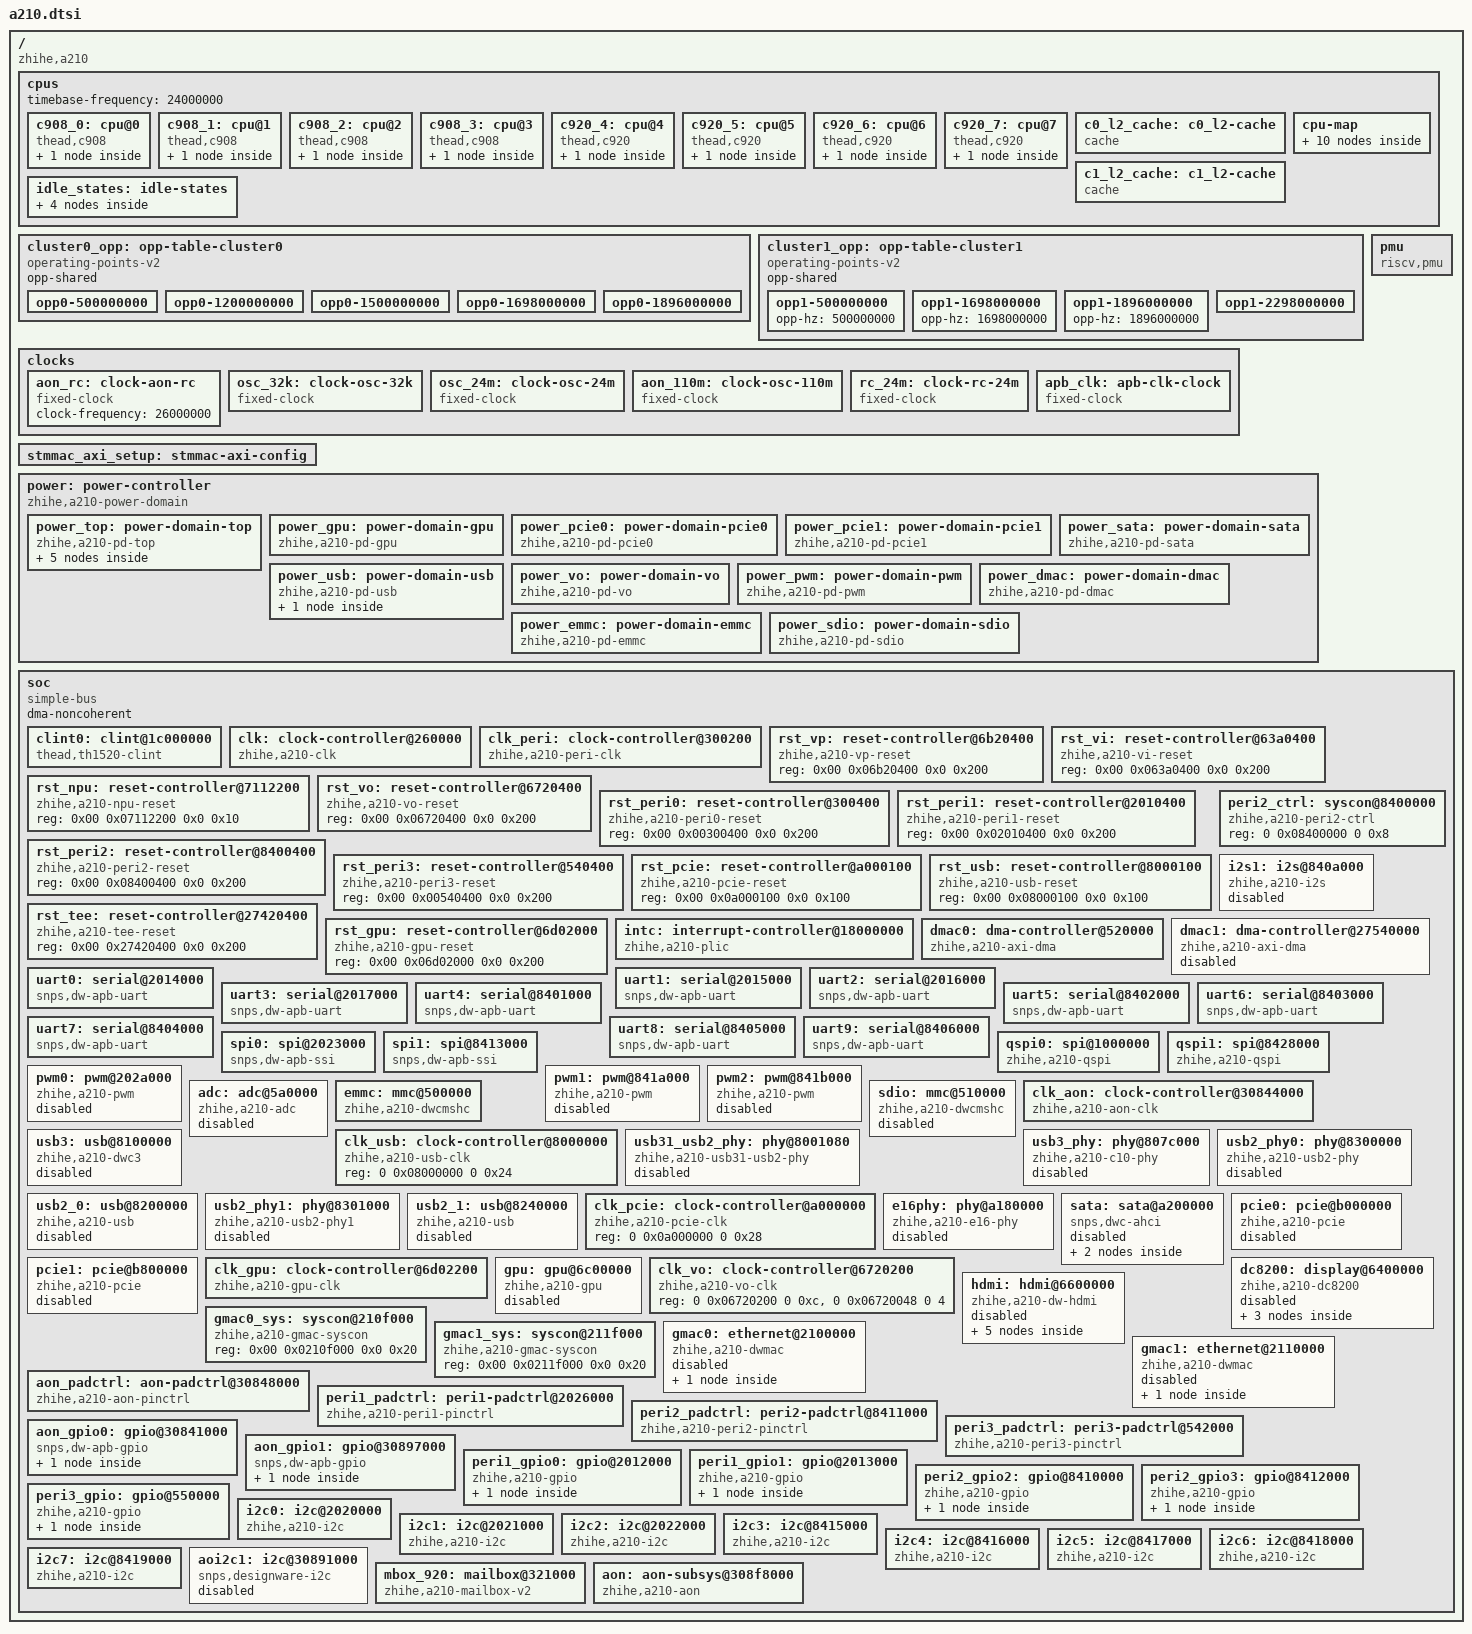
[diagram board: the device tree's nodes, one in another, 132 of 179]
// SPDX-License-Identifier: (GPL-2.0-only OR BSD-2-Clause)
/*
 * Copyright (C) 2021 Alibaba Group Holding Limited.
 */

#include <dt-bindings/ata/ahci.h>
#include <dt-bindings/clock/zhihe,a210-clk.h>
#include <dt-bindings/clock/zhihe,a210-aon-clk.h>
#include <dt-bindings/i2c/i2c.h>
#include <dt-bindings/interrupt-controller/irq.h>
#include <dt-bindings/reset/zhihe,a210-resets.h>

/ {
	compatible = "zhihe,a210";
	#address-cells = <2>;
	#size-cells = <2>;

	cpus: cpus {
		#address-cells = <1>;
		#size-cells = <0>;
		timebase-frequency = <24000000>; /*24M*/
		c908_0: cpu@0 {
			device_type = "cpu";
			reg = <0>;
			compatible = "thead,c908", "riscv";
			riscv,isa-base = "rv64i";
			riscv,isa-extensions = "i", "m", "a", "f", "d", "c", "b", "v",
					     "sscofpmf", "sstc", "svpbmt", "zba", "zbb",
					     "zbc", "zbs", "zicbom", "zicbop",
					     "zicboz", "zicntr", "zicsr",
					     "zifencei", "zihpm";
			riscv,cbom-block-size = <64>;
			riscv,cbop-block-size = <64>;
			riscv,cboz-block-size = <64>;
			mmu-type = "riscv,sv39";
			i-cache-block-size = <64>;
			i-cache-size = <32768>;
			i-cache-sets = <256>;
			d-cache-block-size = <64>;
			d-cache-size = <32768>;
			d-cache-sets = <256>;
			next-level-cache = <&c0_l2_cache>;
			capacity-dmips-mhz = <768>;
			clocks = <&clk C908_CPU_TO_CDE_CLK_MUX>;
			operating-points-v2 = <&cluster0_opp>;
			#cooling-cells = <2>;
			numa-node-id = <0>;
			status = "okay";
			cpu0_intc: interrupt-controller {
				#interrupt-cells = <1>;
				compatible = "riscv,cpu-intc";
				interrupt-controller;
			};
		};
		c908_1: cpu@1 {
			device_type = "cpu";
			reg = <1>;
			compatible = "thead,c908", "riscv";
			riscv,isa-base = "rv64i";
			riscv,isa-extensions = "i", "m", "a", "f", "d", "c", "b", "v",
					     "sscofpmf", "sstc", "svpbmt", "zba", "zbb",
					     "zbc", "zbs", "zicbom", "zicbop",
					     "zicboz", "zicntr", "zicsr",
					     "zifencei", "zihpm";
			riscv,cbom-block-size = <64>;
			riscv,cbop-block-size = <64>;
			riscv,cboz-block-size = <64>;
			mmu-type = "riscv,sv39";
			i-cache-block-size = <64>;
			i-cache-size = <32768>;
			i-cache-sets = <256>;
			d-cache-block-size = <64>;
			d-cache-size = <32768>;
			d-cache-sets = <256>;
			next-level-cache = <&c0_l2_cache>;
			capacity-dmips-mhz = <768>;
			operating-points-v2 = <&cluster0_opp>;
			#cooling-cells = <2>;
			numa-node-id = <0>;
			status = "okay";
			cpu1_intc: interrupt-controller {
				#interrupt-cells = <1>;
				compatible = "riscv,cpu-intc";
				interrupt-controller;
			};
		};
		c908_2: cpu@2 {
			device_type = "cpu";
			reg = <2>;
			compatible = "thead,c908", "riscv";
			riscv,isa-base = "rv64i";
			riscv,isa-extensions = "i", "m", "a", "f", "d", "c", "b", "v",
					     "sscofpmf", "sstc", "svpbmt", "zba", "zbb",
					     "zbc", "zbs", "zicbom", "zicbop",
					     "zicboz", "zicntr", "zicsr",
					     "zifencei", "zihpm";
			riscv,cbom-block-size = <64>;
			riscv,cbop-block-size = <64>;
			riscv,cboz-block-size = <64>;
			mmu-type = "riscv,sv39";
			i-cache-block-size = <64>;
			i-cache-size = <32768>;
			i-cache-sets = <256>;
			d-cache-block-size = <64>;
			d-cache-size = <32768>;
			d-cache-sets = <256>;
			next-level-cache = <&c0_l2_cache>;
			capacity-dmips-mhz = <768>;
			operating-points-v2 = <&cluster0_opp>;
			#cooling-cells = <2>;
			numa-node-id = <0>;
			status = "okay";
			cpu2_intc: interrupt-controller {
				#interrupt-cells = <1>;
				compatible = "riscv,cpu-intc";
				interrupt-controller;
			};
		};
		c908_3: cpu@3 {
			device_type = "cpu";
			reg = <3>;
			compatible = "thead,c908", "riscv";
			riscv,isa-base = "rv64i";
			riscv,isa-extensions = "i", "m", "a", "f", "d", "c", "b", "v",
					     "sscofpmf", "sstc", "svpbmt", "zba", "zbb",
					     "zbc", "zbs", "zicbom", "zicbop",
					     "zicboz", "zicntr", "zicsr",
					     "zifencei", "zihpm";
			riscv,cbom-block-size = <64>;
			riscv,cbop-block-size = <64>;
			riscv,cboz-block-size = <64>;
			mmu-type = "riscv,sv39";
			i-cache-block-size = <64>;
			i-cache-size = <32768>;
			i-cache-sets = <256>;
			d-cache-block-size = <64>;
			d-cache-size = <32768>;
			d-cache-sets = <256>;
			next-level-cache = <&c0_l2_cache>;
			capacity-dmips-mhz = <768>;
			operating-points-v2 = <&cluster0_opp>;
			#cooling-cells = <2>;
			numa-node-id = <0>;
			status = "okay";
			cpu3_intc: interrupt-controller {
				#interrupt-cells = <1>;
				compatible = "riscv,cpu-intc";
				interrupt-controller;
			};
		};

		c920_4: cpu@4 {
			device_type = "cpu";
			reg = <4>;
			compatible = "thead,c920", "riscv";
			riscv,isa-base = "rv64i";
			riscv,isa-extensions = "i", "m", "a", "f", "d", "c", "b", "v",
					     "sscofpmf", "sstc", "svpbmt", "zba", "zbb",
					     "zbc", "zbs", "zicbom", "zicbop",
					     "zicboz", "zicntr", "zicsr",
					     "zifencei", "zihpm";
			riscv,cbom-block-size = <64>;
			riscv,cbop-block-size = <64>;
			riscv,cboz-block-size = <64>;
			mmu-type = "riscv,sv39";
			i-cache-block-size = <64>;
			i-cache-size = <65536>;
			i-cache-sets = <512>;
			d-cache-block-size = <64>;
			d-cache-size = <65536>;
			d-cache-sets = <512>;
			next-level-cache = <&c1_l2_cache>;
			capacity-dmips-mhz = <1024>;
			clocks = <&clk C920_CPU_TO_CDE_CLK_MUX>;
			operating-points-v2 = <&cluster1_opp>;
			#cooling-cells = <2>;
			numa-node-id = <0>;
			status = "okay";
			cpu4_intc: interrupt-controller {
				#interrupt-cells = <1>;
				compatible = "riscv,cpu-intc";
				interrupt-controller;
			};
		};
		c920_5: cpu@5 {
			device_type = "cpu";
			reg = <5>;
			compatible = "thead,c920", "riscv";
			riscv,isa-base = "rv64i";
			riscv,isa-extensions = "i", "m", "a", "f", "d", "c", "b", "v",
					     "sscofpmf", "sstc", "svpbmt", "zba", "zbb",
					     "zbc", "zbs", "zicbom", "zicbop",
					     "zicboz", "zicntr", "zicsr",
					     "zifencei", "zihpm";
			riscv,cbom-block-size = <64>;
			riscv,cbop-block-size = <64>;
			riscv,cboz-block-size = <64>;
			mmu-type = "riscv,sv39";
			i-cache-block-size = <64>;
			i-cache-size = <65536>;
			i-cache-sets = <512>;
			d-cache-block-size = <64>;
			d-cache-size = <65536>;
			d-cache-sets = <512>;
			next-level-cache = <&c1_l2_cache>;
			capacity-dmips-mhz = <1024>;
			operating-points-v2 = <&cluster1_opp>;
			#cooling-cells = <2>;
			numa-node-id = <0>;
			status = "okay";
			cpu5_intc: interrupt-controller {
				#interrupt-cells = <1>;
				compatible = "riscv,cpu-intc";
				interrupt-controller;
			};
		};
		c920_6: cpu@6 {
			device_type = "cpu";
			reg = <6>;
			compatible = "thead,c920", "riscv";
			riscv,isa-base = "rv64i";
			riscv,isa-extensions = "i", "m", "a", "f", "d", "c", "b", "v",
					     "sscofpmf", "sstc", "svpbmt", "zba", "zbb",
					     "zbc", "zbs", "zicbom", "zicbop",
					     "zicboz", "zicntr", "zicsr",
					     "zifencei", "zihpm";
			riscv,cbom-block-size = <64>;
			riscv,cbop-block-size = <64>;
			riscv,cboz-block-size = <64>;
			mmu-type = "riscv,sv39";
			i-cache-block-size = <64>;
			i-cache-size = <65536>;
			i-cache-sets = <512>;
			d-cache-block-size = <64>;
			d-cache-size = <65536>;
			d-cache-sets = <512>;
			next-level-cache = <&c1_l2_cache>;
			capacity-dmips-mhz = <1024>;
			operating-points-v2 = <&cluster1_opp>;
			#cooling-cells = <2>;
			numa-node-id = <0>;
			status = "okay";
			cpu6_intc: interrupt-controller {
				#interrupt-cells = <1>;
				compatible = "riscv,cpu-intc";
				interrupt-controller;
			};
		};
		c920_7: cpu@7 {
			device_type = "cpu";
			reg = <7>;
			compatible = "thead,c920", "riscv";
			riscv,isa-base = "rv64i";
			riscv,isa-extensions = "i", "m", "a", "f", "d", "c", "b", "v",
					     "sscofpmf", "sstc", "svpbmt", "zba", "zbb",
					     "zbc", "zbs", "zicbom", "zicbop",
					     "zicboz", "zicntr", "zicsr",
					     "zifencei", "zihpm";
			riscv,cbom-block-size = <64>;
			riscv,cbop-block-size = <64>;
			riscv,cboz-block-size = <64>;
			mmu-type = "riscv,sv39";
			i-cache-block-size = <64>;
			i-cache-size = <65536>;
			i-cache-sets = <512>;
			d-cache-block-size = <64>;
			d-cache-size = <65536>;
			d-cache-sets = <512>;
			next-level-cache = <&c1_l2_cache>;
			capacity-dmips-mhz = <1024>;
			operating-points-v2 = <&cluster1_opp>;
			#cooling-cells = <2>;
			numa-node-id = <0>;
			status = "okay";
			cpu7_intc: interrupt-controller {
				#interrupt-cells = <1>;
				compatible = "riscv,cpu-intc";
				interrupt-controller;
			};
		};

		c0_l2_cache: c0_l2-cache {
			compatible = "cache";
			cache-block-size = <64>;
			cache-level = <2>;
			cache-size = <524288>;
			cache-sets = <512>;
			cache-unified;
		};
		c1_l2_cache: c1_l2-cache {
			compatible = "cache";
			cache-block-size = <64>;
			cache-level = <2>;
			cache-size = <1048576>;
			cache-sets = <1024>;
			cache-unified;
		};

		cpu-map {
			cluster0 {
				core0 {
					cpu = <&c908_0>;
				};

				core1 {
					cpu = <&c908_1>;
				};

				core2 {
					cpu = <&c908_2>;
				};

				core3 {
					cpu = <&c908_3>;
				};
			};
			cluster1 {
				core0 {
					cpu = <&c920_4>;
				};

				core1 {
					cpu = <&c920_5>;
				};

				core2 {
					cpu = <&c920_6>;
				};

				core3 {
					cpu = <&c920_7>;
				};
			};
		};

		idle_states: idle-states {
			CPU_RET_0_0: cpu-retentive-0-0 {
				compatible = "riscv,idle-state";
				riscv,sbi-suspend-param = <0x10000000>;
				entry-latency-us = <20>;
				exit-latency-us = <40>;
				min-residency-us = <80>;
			};

			CPU_NONRET_0_0: cpu-nonretentive-0-0 {
				compatible = "riscv,idle-state";
				riscv,sbi-suspend-param = <0x90000000>;
				entry-latency-us = <250>;
				exit-latency-us = <500>;
				min-residency-us = <950>;
			};

			CLUSTER_RET_0: cluster-retentive-0 {
				compatible = "riscv,idle-state";
				riscv,sbi-suspend-param = <0x11000000>;
				local-timer-stop;
				entry-latency-us = <50>;
				exit-latency-us = <100>;
				min-residency-us = <250>;
				wakeup-latency-us = <130>;
			};

			CLUSTER_NONRET_0: cluster-nonretentive-0 {
				compatible = "riscv,idle-state";
				riscv,sbi-suspend-param = <0x91000000>;
				local-timer-stop;
				entry-latency-us = <600>;
				exit-latency-us = <1100>;
				min-residency-us = <2700>;
				wakeup-latency-us = <1500>;
			};
		};
	};

	cluster0_opp: opp-table-cluster0 {
		compatible = "operating-points-v2";
		opp-shared;
		opp0-500000000 {
			opp-hz = /bits/ 64 <500000000>;
			bus-clk-hz = /bits/ 64 <196608000>;
			pic-clk-hz = /bits/ 64 <250000000>;
			cfg-clk-hz = /bits/ 64 <110000000>;
			com-clk-hz = /bits/ 64 <82500000>;
			apb-clk-hz = /bits/ 64 <82500000>;
		};
		opp0-1200000000 {
			opp-hz = /bits/ 64 <1200000000>;
			bus-clk-hz = /bits/ 64 <660000000>;
			pic-clk-hz = /bits/ 64 <500000000>;
			cfg-clk-hz = /bits/ 64 <220000000>;
			com-clk-hz = /bits/ 64 <165000000>;
			apb-clk-hz = /bits/ 64 <165000000>;
		};
		opp0-1500000000 {
			opp-hz = /bits/ 64 <1500000000>;
			bus-clk-hz = /bits/ 64 <1000000000>;
			pic-clk-hz = /bits/ 64 <1000000000>;
			cfg-clk-hz = /bits/ 64 <330000000>;
			com-clk-hz = /bits/ 64 <165000000>;
			apb-clk-hz = /bits/ 64 <165000000>;
		};
		opp0-1698000000 {
			opp-hz = /bits/ 64 <1698000000>;
			bus-clk-hz = /bits/ 64 <1100000000>;
			pic-clk-hz = /bits/ 64 <1000000000>;
			cfg-clk-hz = /bits/ 64 <330000000>;
			com-clk-hz = /bits/ 64 <165000000>;
			apb-clk-hz = /bits/ 64 <165000000>;
		};
		opp0-1896000000 {
			opp-hz = /bits/ 64 <1896000000>;
			bus-clk-hz = /bits/ 64 <1320000000>;
			pic-clk-hz = /bits/ 64 <1000000000>;
			cfg-clk-hz = /bits/ 64 <330000000>;
			com-clk-hz = /bits/ 64 <165000000>;
			apb-clk-hz = /bits/ 64 <165000000>;
		};
	};

	cluster1_opp: opp-table-cluster1 {
		compatible = "operating-points-v2";
		opp-shared;
		opp1-500000000 {
			opp-hz = /bits/ 64 <500000000>;
		};
		opp1-1698000000 {
			opp-hz = /bits/ 64 <1698000000>;
		};
		opp1-1896000000 {
			opp-hz = /bits/ 64 <1896000000>;
		};
		opp1-2298000000 {
			opp-hz = /bits/ 64 <2298000000>;
			turbo-mode;
		};
	};

	pmu {
		compatible = "riscv,pmu";
		riscv,event-to-mhpmevent =
			/* PMU_HW_CPU_CYCLES:1 */
			<0x00001 0x00000000 0x00000000>,
			/* PMU_HW_INSTRUCTIONS:2 */
			<0x00002 0x00000000 0x00000000>,
			/* PMU_HW_CACHE_REFERENCES:3 */
			/* PMU_HW_CACHE_MISSES:4 */
			/* PMU_HW_BRANCH_INSTRUCTIONS:5 */
			<0x00005 0x00000000 0x00000007>,
			/* PMU_HW_BRANCH_MISSES:6 */
			<0x00006 0x00000000 0x00000006>,
			/* PMU_HW_BUS_CYCLES:7 */
			/* PMU_HW_STALLED_CYCLES_FRONTEND:8 */
			<0x00008 0x00000000 0x00000027>,
			/* PMU_HW_STALLED_CYCLES_BACKEND:9 */
			<0x00009 0x00000000 0x00000028>,
			/* PMU_HW_REF_CPU_CYCLES:10 */
			/* L1D_READ_ACCESS:0x10000 */
			<0x10000 0x00000000 0x0000000c>,
			/* L1D_READ_MISS:0x10001 */
			<0x10001 0x00000000 0x0000000d>,
			/* L1D_WRITE_ACCESS:0x10002 */
			<0x10002 0x00000000 0x0000000e>,
			/* L1D_WRITE_MISS:0x10003 */
			<0x10003 0x00000000 0x0000000f>,
			/* L1I_READ_ACCESS:0x10008 */
			<0x10008 0x00000000 0x00000001>,
			/* L1I_READ_MISS:0x10009 */
			<0x10009 0x00000000 0x00000002>,
			/* dTLB read miss :0x10019 */
			<0x10019 0x00000000 0x00000004>,
			/* iTLB read miss :0x10021 */
			<0x10021 0x00000000 0x00000003>;
			/* LL_READ_ACCESS:0x10010 */
			/* LL_READ_MISS:0x10011 */
			/* LL_WRITE_ACCESS:0x10012 */
			/* LL_WRITE_MISS:0x10013 */
			/* BPU_READ_ACCESS:0x10028 */
			/* BPU_READ_MISS:0x10029 */
		riscv,event-to-mhpmcounters =
			/* 31 mhpmcounters, bitmap 0xfffffff8 */
			<0x00001 0x00001 0x00000001>,
			<0x00002 0x00002 0x00000004>,
			<0x00005 0x00005 0xfffffff8>,
			<0x00006 0x00006 0xfffffff8>,
			<0x00008 0x00008 0xfffffff8>,
			<0x00009 0x00009 0xfffffff8>,
			<0x10000 0x10000 0xfffffff8>,
			<0x10001 0x10001 0xfffffff8>,
			<0x10002 0x10002 0xfffffff8>,
			<0x10003 0x10003 0xfffffff8>,
			<0x10008 0x10008 0xfffffff8>,
			<0x10009 0x10009 0xfffffff8>,
			<0x10019 0x10019 0xfffffff8>,
			<0x10021 0x10021 0xfffffff8>;
		riscv,raw-event-to-mhpmcounters =
			/* For raw event ID 0x0 - 0xff */
			<0x0 0x0 0xffffffff 0xffffff00 0xfffffff8>;
	};

	clocks {


		aon_rc: clock-aon-rc {
			compatible = "fixed-clock";
			#clock-cells = <0>;
			clock-frequency = <26000000>;
		};

		osc_32k: clock-osc-32k {
			compatible = "fixed-clock";
			clock-frequency = <32768>;
			clock-output-names = "osc-32k";
			#clock-cells = <0>;
		};

		osc_24m: clock-osc-24m {
			compatible = "fixed-clock";
			clock-frequency = <24000000>;
			clock-output-names = "osc-24m";
			#clock-cells = <0>;
		};

		aon_110m: clock-osc-110m {
			compatible = "fixed-clock";
			clock-frequency = <110000000>;
			clock-output-names = "aon-110m";
			#clock-cells = <0>;
		};

		rc_24m: clock-rc-24m {
			compatible = "fixed-clock";
			clock-frequency = <24000000>;
			clock-output-names = "rc-24m";
			#clock-cells = <0>;
		};

		apb_clk: apb-clk-clock {
			compatible = "fixed-clock";
			clock-frequency = <62500000>;
			clock-output-names = "apb-clk";
			#clock-cells = <0>;
		};
	};

	stmmac_axi_setup: stmmac-axi-config {
		snps,wr_osr_lmt = <7>;
		snps,rd_osr_lmt = <7>;
		snps,blen = <16 8 4 0 0 0 0>;
	};

	power: power-controller {
		compatible = "zhihe,a210-power-domain";
		#power-domain-cells = <0>;
		#address-cells = <2>;
		#size-cells = <2>;
		ranges;

		power_top: power-domain-top {
			compatible = "zhihe,a210-pd-top";
			#power-domain-cells = <0>;
			#address-cells = <2>;
			#size-cells = <2>;
			ranges;
			ddr_ccu: clock-controller@5910000 {
				compatible = "zhihe,a210-ccu";
				reg = <0x00 0x05910000 0x0 0x2C>,
				      <0x00 0x05920000 0x0 0x2C>;
				zhihe,ccu-dly-time = <0x5E 0x5E>;
				zhihe,ccu-dly-time-step = <0x3 0x3>;
			};
			pcie_ccu: clock-controller@a007400 {
				compatible = "zhihe,a210-ccu";
				reg = <0x00 0x0A007400 0x0 0x2C>,
				      <0x00 0x0A008000 0x0 0x2C>,
				      <0x00 0x0A008400 0x0 0x2C>;
				zhihe,ccu-dly-time = <0x5E 0x5E 0x5E>;
				zhihe,ccu-dly-time-step = <0x3 0x3 0x3>;
			};
			tee_ccu: clock-controller@27430000 {
				compatible = "zhihe,a210-ccu";
				reg = <0x00 0x27430000 0x0 0x2C>;
				zhihe,ccu-dly-time = <0x5E>;
				zhihe,ccu-dly-time-step = <0x3>;
			};
			cpu_gating_ccu: clock-controller@10140000 {
				compatible = "zhihe,a210-ccu";
				reg = <0x00 0x10140000 0x0 0x2C>,
				      <0x00 0x10140200 0x0 0x2C>,
				      <0x00 0x10140400 0x0 0x2C>,
				      <0x00 0x10140600 0x0 0x2C>,
				      <0x00 0x10140A00 0x0 0x2C>,
				      <0x00 0x10140C00 0x0 0x2C>,
				      <0x00 0x10204000 0x0 0x2C>,
				      <0x00 0x10204200 0x0 0x2C>,
				      <0x00 0x10204400 0x0 0x2C>,
				      <0x00 0x10204600 0x0 0x2C>,
				      <0x00 0x10204800 0x0 0x2C>,
				      <0x00 0x10204A00 0x0 0x2C>,
				      <0x00 0x10205400 0x0 0x2C>;
				zhihe,ccu-dly-time = <0x34 0x34 0x34
						      0x34 0x34 0x34
						      0x34 0x34 0x34
						      0x34 0x34 0x34
						      0x34>;
				zhihe,ccu-dly-time-step = <0x2 0x2 0x2
							   0x2 0x2 0x2
							   0x2 0x2 0x2
							   0x2 0x2 0x2
							   0x2>;
			};
			cpu_scaling_ccu: clock-controller@10140800 {
				compatible = "zhihe,a210-ccu";
				reg = <0x00 0x10140800 0x0 0x2C>;
				zhihe,ccu-mode = <1>;
				zhihe,ccu-dly-time = <0x34>;
				zhihe,ccu-dly-time-step = <0x2>;
				zhihe,ccu-ratio = <63>;
			};
		};
		power_gpu: power-domain-gpu {
			compatible = "zhihe,a210-pd-gpu";
			reg = <0 0x06e00600 0 0x200>,
			      <0 0x06e00400 0 0x200>,
			      <0 0x06e00000 0 0x200>,
			      <0 0x26d12000 0 0x1000>;
			reg-names = "pca", "bpc", "pcu", "iopmp";
			power-domains = <&power_top>;
			clocks = <&clk TOP_GPU_CORE_CLK_DIV>;
			#power-domain-cells = <0>;
		};

		power_pcie0: power-domain-pcie0 {
			compatible = "zhihe,a210-pd-pcie0";
			reg = <0 0x0a006200 0 0x200>,
			      <0 0x0a006000 0 0x200>;
			reg-names = "bpc", "pcu";
			power-domains = <&power_top>;
			#power-domain-cells = <0>;
		};

		power_pcie1: power-domain-pcie1 {
			compatible = "zhihe,a210-pd-pcie1";
			reg = <0 0x0a006600 0 0x200>,
			      <0 0x0a006400 0 0x200>;
			reg-names = "bpc", "pcu";
			power-domains = <&power_top>;
			#power-domain-cells = <0>;
		};

		power_sata: power-domain-sata {
			compatible = "zhihe,a210-pd-sata";
			reg = <0 0x0a006a00 0 0x200>,
			      <0 0x0a006800 0 0x200>;
			reg-names = "bpc", "pcu";
			power-domains = <&power_top>;
			clocks = <&clk_pcie SATA_GEN3X2_ACLK_EN>,
				 <&clk_pcie SATA_PMALIVE_CLK_EN>,
				 <&clk_pcie SATA_MST_AFENCE_ACLK_EN>,
				 <&clk_pcie SATA_SLV_AFENCE_ACLK_EN>,
				 <&clk_pcie X2X_SATA_SLV_ACLK_EN>,
				 <&clk_pcie X2X_SATA_MST_ACLK_EN>,
				 <&clk_pcie SATA_RXOOB0_CLK_EN>,
				 <&clk_pcie SATA_RXOOB1_CLK_EN>;
			resets = <&rst_pcie PCIE_X2X_SATA_MST_ARST>,
				 <&rst_pcie PCIE_X2X_SATA_SLV_ARST>,
				 <&rst_pcie PCIE_SATA_SLV_AFENCE_ARST>,
				 <&rst_pcie PCIE_SATA_MST_AFENCE_ARST>,
				 <&rst_pcie PCIE_SATA_RST_ASIC0>,
				 <&rst_pcie PCIE_SATA_RST_ASIC1>,
				 <&rst_pcie PCIE_SATA_RST_RXOOB0>,
				 <&rst_pcie PCIE_SATA_RST_RXOOB1>;
			#power-domain-cells = <0>;
		};

		power_usb: power-domain-usb {
			compatible = "zhihe,a210-pd-usb";
			power-domains = <&power_top>;
			clocks = <&clk_usb USB_SS_AXI_MST_PCLK_EN>,
				 <&clk_usb USB_SS_AXI_MST_ACLK_EN>,
				 <&clk_usb USB_SS_DFMU_IOMMU_PTW_ACLK_EN>,
				 <&clk_usb USB_SS_DFMU_ACLK_EN>,
				 <&clk_usb USB_SS_DFMU_PCLK_EN>,
				 <&clk_usb USB31_SLV_AFENCE_ACLK_EN>,
				 <&clk_usb USB20_X2H_HCLK>,
				 <&clk_usb USB20_X2H_ACLK>,
				 <&clk_usb USB20_SLV_AFENCE_ACLK>,
				 <&clk_usb USB20_H2P_HCLK>,
				 <&clk_usb USB20_AHB_SLV_HCLK>,
				 <&clk_usb USB20_SYSREG_PCLK>,
				 <&clk_usb USB20_A2X0_HCLK>,
				 <&clk_usb USB20_A2X0_ACLK>,
				 <&clk_usb USB20_A2X1_HCLK>,
				 <&clk_usb USB20_A2X1_ACLK>,
				 <&clk_usb USB20_BUS_CLK>;
			resets = <&rst_usb USB_DFMU_PRST>,
				 <&rst_usb USB_DFMU_ARST>,
				 <&rst_usb USB_AXI4_MST_ARST>,
				 <&rst_usb USB_AXI4_MST_PRST>,
				 <&rst_usb USB_USB31_SLV_AFENCE_ARST>,
				 <&rst_usb USB_USB31_APBS_PRST>,
				 <&rst_usb USB_USB20_BLK_X2H_HRST>,
				 <&rst_usb USB_USB20_BLK_X2H_ARST>,
				 <&rst_usb USB_USB20_SLV_AFENCE_ARST>,
				 <&rst_usb USB_USB20_BLK_H2P_HRST>,
				 <&rst_usb USB_USB20_BLK_AHB_SLV_HRST>,
				 <&rst_usb USB_USB20_BLK_AXI_MST_ARST>,
				 <&rst_usb USB_USB20_BLK_USB2_SYSREG_PRST>,
				 <&rst_usb USB_USB20_BLK_USB2_WRAP0_PRST>,
				 <&rst_usb USB_USB20_BLK_USB2_WRAP1_PRST>,
				 <&rst_usb USB_USB20_BLK_A2X0_HRST>,
				 <&rst_usb USB_USB20_BLK_A2X0_ARST>,
				 <&rst_usb USB_USB20_BLK_A2X1_HRST>,
				 <&rst_usb USB_USB20_BLK_A2X1_ARST>;
			#power-domain-cells = <0>;
			#address-cells = <2>;
			#size-cells = <2>;
			ranges;

			usb_ccu: clock-controller@0 {
				compatible = "zhihe,a210-ccu";
				reg = <0x00 0x08004400 0x0 0x2C>,
				      <0x00 0x08006000 0x0 0x2C>,
				      <0x00 0x08006400 0x0 0x2C>;
				zhihe,ccu-dly-time = <0x5E 0x5E 0x5E>;
				zhihe,ccu-dly-time-step = <0x3 0x3 0x3>;
			};
		};

		power_vo: power-domain-vo {
			compatible = "zhihe,a210-pd-vo";
			reg = <0 0x067f1000 0 0x200>,
			      <0 0x067f0000 0 0x200>,
			      <0 0x06720000 0 0x1000>,
			      <0 0x26712000 0 0x1000>;
			reg-names = "bpc", "pcu", "syscon", "iopmp";
			power-domains = <&power_top>;
			clocks = <&clk_vo VO_X2H0_CLK_EN>,
				 <&clk_vo VO_X2H1_CLK_EN>,
				 <&clk_vo VO_ARB_PCLK_EN>,
				 <&clk_vo VO_ARB_ACLK_EN>,
				 <&clk_vo VO_DFMU_PCLK_EN>,
				 <&clk_vo VO_DFMU_ACLK_EN>,
				 <&clk_vo VO_PTW_ACLK_EN>;
			resets = <&rst_vo VO_X2H0_RST>, <&rst_vo VO_X2H1_RST>,
				 <&rst_vo VO_ARB_PRST>, <&rst_vo VO_ARB_ARST>,
				 <&rst_vo VO_DFMU_PRST>, <&rst_vo VO_DFMU_ARST>;
			#power-domain-cells = <0>;
		};

		power_pwm: power-domain-pwm {
			compatible = "zhihe,a210-pd-pwm";
			power-domains = <&power_top>;
			resets = <&rst_peri1 PERI1_PWM0_CRST>,
				 <&rst_peri1 PERI1_PWM0_PRST>,
				 <&rst_peri2 PERI2_PWM1_CRST>,
				 <&rst_peri2 PERI2_PWM1_PRST>,
				 <&rst_peri2 PERI2_PWM2_CRST>,
				 <&rst_peri2 PERI2_PWM2_PRST>;
			#power-domain-cells = <0>;
		};

		power_dmac: power-domain-dmac {
			compatible = "zhihe,a210-pd-dmac";
			power-domains = <&power_top>;
			clocks = <&clk_peri AXI_PERI3_MST_ACLK_EN>,
				 <&clk_peri AXI_PERI3_MST_PCLK_EN>;
			#power-domain-cells = <0>;
		};

		power_emmc: power-domain-emmc {
			compatible = "zhihe,a210-pd-emmc";
			power-domains = <&power_top>;
			#power-domain-cells = <0>;
			clocks = <&clk_peri AXI_PERI3_MST_ACLK_EN>,
				 <&clk_peri AXI_PERI3_MST_PCLK_EN>,
				 <&clk_peri PERI3_EMMC_ACLK_EN>,
				<&clk_peri PERI3_EMMC_X2X_ACLK_S_EN>,
				<&clk_peri PERI3_EMMC_X2X_ACLK_M_EN>,
				<&clk_peri PERI3_EMMC_OSC_CLK_EN>;
		};
		power_sdio: power-domain-sdio {
			compatible = "zhihe,a210-pd-sdio";
			power-domains = <&power_top>;
			#power-domain-cells = <0>;
			clocks = <&clk_peri AXI_PERI3_MST_ACLK_EN>,
				 <&clk_peri AXI_PERI3_MST_PCLK_EN>,
				 <&clk_peri PERI3_SDIO_ACLK_EN>,
				<&clk_peri PERI3_SDIO_X2X_ACLK_S_EN>,
				<&clk_peri PERI3_SDIO_X2X_ACLK_M_EN>,
				<&clk_peri PERI3_SDIO_OSC_CLK_EN>;
		};
	};

	soc {
		compatible = "simple-bus";
		#address-cells = <2>;
		#size-cells = <2>;
		ranges;
		dma-noncoherent;

		clint0: clint@1c000000 {
			compatible = "thead,th1520-clint", "thead,c900-clint";
			interrupts-extended = <
				&cpu0_intc  3 &cpu0_intc  7
				&cpu1_intc  3 &cpu1_intc  7
				&cpu2_intc  3 &cpu2_intc  7
				&cpu3_intc  3 &cpu3_intc  7
				&cpu4_intc  3 &cpu4_intc  7
				&cpu5_intc  3 &cpu5_intc  7
				&cpu6_intc  3 &cpu6_intc  7
				&cpu7_intc  3 &cpu7_intc  7
			>;
			reg = <0x00 0x1c000000 0x0 0x0000d800>;
		};

		clk: clock-controller@260000 {
			compatible = "zhihe,a210-clk";
			reg = <0x00 0x00260000 0x0 0x1000>,<0x00 0x00250000 0x0 0x1000>,
			      <0x00 0x10141600 0x0 0x100>,<0x00 0x10141400 0x0 0x100>,
			      <0x00 0x04810000 0x0 0x1000>,<0x00 0x05810000 0x0 0x1000>,
			      <0x00 0x04900000 0x0 0x1000>,<0x00 0x20250000 0x0 0x1000>,
			      <0x00 0x10140000 0x0 0xE00>;
			reg-names = "pll-wrap","top-crg","cpu-ss-clk-sysreg","cpu-ss-cpu-pll",
			"ddr0-sysreg","ddr1-sysreg","slc-dual-sysreg","top-crg-t","cpu-ss-ccu";
			#clock-cells = <1>;
			clocks = <&osc_32k>, <&osc_24m>, <&rc_24m>;
			clock-names = "osc-32k", "osc-24m", "rc-24m";
			status = "okay";
		};

		clk_peri: clock-controller@300200 {
			compatible = "zhihe,a210-peri-clk";
			reg = <0x00 0x00300200 0x0 0x4>,
			      <0x00 0x02010200 0x0 0x8>,<0x00 0x08400200 0x0 0x8>,
			      <0x00 0x00540200 0x0 0x4>,<0x00 0x27420200 0x0 0x200>;
			reg-names = "peri0-sysreg","peri1-sysreg","peri2-sysreg",
			"peri3-sysreg","tee-crg";
			#clock-cells = <1>;
			status = "okay";
		};

		rst_vp: reset-controller@6b20400 {
			compatible = "zhihe,a210-vp-reset";
			reg = <0x00 0x06b20400 0x0 0x200>;
			#reset-cells = <1>;
		};

		rst_vi: reset-controller@63a0400 {
			compatible = "zhihe,a210-vi-reset";
			reg = <0x00 0x063a0400 0x0 0x200>;
			#reset-cells = <1>;
		};

		rst_npu: reset-controller@7112200 {
			compatible = "zhihe,a210-npu-reset";
			reg = <0x00 0x07112200 0x0 0x10>;
			#reset-cells = <1>;
		};

		rst_vo: reset-controller@6720400 {
			compatible = "zhihe,a210-vo-reset";
			reg = <0x00 0x06720400 0x0 0x200>;
			#reset-cells = <1>;
		};

		rst_peri0: reset-controller@300400 {
			compatible = "zhihe,a210-peri0-reset";
			reg = <0x00 0x00300400 0x0 0x200>;
			#reset-cells = <1>;
		};

		rst_peri1: reset-controller@2010400 {
			compatible = "zhihe,a210-peri1-reset";
			reg = <0x00 0x02010400 0x0 0x200>;
			#reset-cells = <1>;
		};

		rst_peri2: reset-controller@8400400 {
			compatible = "zhihe,a210-peri2-reset";
			reg = <0x00 0x08400400 0x0 0x200>;
			#reset-cells = <1>;
		};

		rst_peri3: reset-controller@540400 {
			compatible = "zhihe,a210-peri3-reset";
			reg = <0x00 0x00540400 0x0 0x200>;
			#reset-cells = <1>;
		};

		rst_pcie: reset-controller@a000100 {
			compatible = "zhihe,a210-pcie-reset";
			reg = <0x00 0x0a000100 0x0 0x100>;
			#reset-cells = <1>;
		};

		rst_usb: reset-controller@8000100 {
			compatible = "zhihe,a210-usb-reset";
			reg = <0x00 0x08000100 0x0 0x100>;
			#reset-cells = <1>;
		};

		rst_tee: reset-controller@27420400 {
			compatible = "zhihe,a210-tee-reset";
			reg = <0x00 0x27420400 0x0 0x200>;
			#reset-cells = <1>;
		};

		rst_gpu: reset-controller@6d02000 {
			compatible = "zhihe,a210-gpu-reset";
			reg = <0x00 0x06d02000 0x0 0x200>;
			#reset-cells = <1>;
		};

		intc: interrupt-controller@18000000 {
			compatible = "zhihe,a210-plic", "thead,c900-plic";
			#address-cells = <0>;
			#interrupt-cells = <2>;
			interrupt-controller;
			interrupts-extended = <
				&cpu0_intc 0xffffffff &cpu0_intc 9
				&cpu1_intc 0xffffffff &cpu1_intc 9
				&cpu2_intc 0xffffffff &cpu2_intc 9
				&cpu3_intc 0xffffffff &cpu3_intc 9
				&cpu4_intc 0xffffffff &cpu4_intc 9
				&cpu5_intc 0xffffffff &cpu5_intc 9
				&cpu6_intc 0xffffffff &cpu6_intc 9
				&cpu7_intc 0xffffffff &cpu7_intc 9
			>;
			reg = <0x00 0x18000000 0x0 0x04000000>;
			riscv,ndev = <351>;
		};

		peri2_ctrl: syscon@8400000 {
			compatible = "zhihe,a210-peri2-ctrl", "syscon";
			reg = <0 0x08400000 0 0x8>;
		};

		i2s1: i2s@840a000 {
			compatible = "zhihe,a210-i2s";
			zhihe,syscon = <&peri2_ctrl 0 0x1>;
			reg = <0 0x0840a000 0 0x1000>;
			interrupt-parent = <&intc>;
			interrupts = <302 IRQ_TYPE_LEVEL_HIGH>;
			clocks = <&clk_peri PERI2_I2S1_PCLK_EN>,
				 <&clk_peri PERI2_I2S1_SRC_CLK_EN>;
			clock-names = "pclk", "mclk";
			resets = <&rst_peri2 PERI2_I2S1_PRST>;
			power-domains = <&power_top>;
			dmas = <&dmac0 38>, <&dmac0 37>;
			dma-names = "tx", "rx";
			#sound-dai-cells = <0>;
			status = "disabled";
		};

		dmac0: dma-controller@520000 {
			compatible = "zhihe,a210-axi-dma", "snps,axi-dma-1.01a";
			reg = <0x00 0x00520000 0x0 0x4000>;
			interrupt-parent = <&intc>;
			interrupts = <264 IRQ_TYPE_LEVEL_HIGH>;
			clocks = <&clk_peri PERI3_DMAC_ACLK_EN>, <&clk_peri PERI3_DMAC_HCLK_EN>;
			clock-names = "core-clk", "cfgr-clk";
			resets = <&rst_peri3 PERI3_DMAC_ARST>, <&rst_peri3 PERI3_DMAC_HRST>;
			power-domains = <&power_dmac>;
			#dma-cells = <1>;
			dma-channels = <16>;
			snps,block-size = <65536 65536 65536 65536
					    65536 65536 65536 65536
					    65536 65536 65536 65536
					    65536 65536 65536 65536>;
			snps,priority = <0 0 0 0 0 0 0 0 0 0 0 0 0 0 0 0>;
			snps,dma-masters = <1>;
			snps,data-width = <4>;
			snps,axi-max-burst-len = <4>;
		};

		dmac1: dma-controller@27540000 {
			compatible = "zhihe,a210-axi-dma", "snps,axi-dma-1.01a";
			reg = <0x00 0x27540000 0x0 0x4000>;
			interrupt-parent = <&intc>;
			interrupts = <259 IRQ_TYPE_LEVEL_HIGH>;
			clocks = <&clk_peri TEE_DMAC_CLKEN>, <&clk_peri TEE_DMAC_CLKEN>;
			clock-names = "core-clk", "cfgr-clk";
			resets = <&rst_tee TEE_DMAC_ARST>, <&rst_tee TEE_DMAC_HRST>;
			#dma-cells = <1>;
			dma-channels = <4>;
			snps,block-size = <65536 65536 65536 65536>;
			snps,priority = <0 0 0 0>;
			snps,dma-masters = <1>;
			snps,data-width = <4>;
			snps,axi-max-burst-len = <16>;
			status = "disabled";
		};

		uart0: serial@2014000 {
			compatible = "snps,dw-apb-uart";
			reg = <0x00 0x02014000 0x0 0x400>;
			interrupt-parent = <&intc>;
			interrupts = <321 IRQ_TYPE_LEVEL_HIGH>;
			clocks = <&clk_peri PERI1_UART0_SCLK_EN>, <&clk_peri PERI1_UART0_PCLK_EN>;
			clock-names = "baudclk", "apb_pclk";
			resets = <&rst_peri1 PERI1_UART0_PRST>;
			reg-shift = <2>;
			reg-io-width = <4>;
		};

		uart1: serial@2015000 {
			compatible = "snps,dw-apb-uart";
			reg = <0x00 0x02015000 0x0 0x1000>;
			interrupt-parent = <&intc>;
			interrupts = <322 IRQ_TYPE_LEVEL_HIGH>;
			clocks = <&clk_peri PERI1_UART1_SCLK_EN>, <&clk_peri PERI1_UART1_PCLK_EN>;
			clock-names = "baudclk", "apb_pclk";
			resets = <&rst_peri1 PERI1_UART1_PRST>;
			reg-shift = <2>;
			reg-io-width = <4>;
		};

		uart2: serial@2016000 {
			compatible = "snps,dw-apb-uart";
			reg = <0x00 0x02016000 0x0 0x1000>;
			interrupt-parent = <&intc>;
			interrupts = <323 IRQ_TYPE_LEVEL_HIGH>;
			clocks = <&clk_peri PERI1_UART2_SCLK_EN>, <&clk_peri PERI1_UART2_PCLK_EN>;
			clock-names = "baudclk", "apb_pclk";
			resets = <&rst_peri1 PERI1_UART2_PRST>;
			reg-shift = <2>;
			reg-io-width = <4>;
		};

		uart3: serial@2017000 {
			compatible = "snps,dw-apb-uart";
			reg = <0x00 0x02017000 0x0 0x1000>;
			interrupt-parent = <&intc>;
			interrupts = <324 IRQ_TYPE_LEVEL_HIGH>;
			clocks = <&clk_peri PERI1_UART3_SCLK_EN>, <&clk_peri PERI1_UART3_PCLK_EN>;
			clock-names = "baudclk", "apb_pclk";
			resets = <&rst_peri1 PERI1_UART3_PRST>;
			reg-shift = <2>;
			reg-io-width = <4>;
		};

		uart4: serial@8401000 {
			compatible = "snps,dw-apb-uart";
			reg = <0x00 0x08401000 0x0 0x400>;
			interrupt-parent = <&intc>;
			interrupts = <325 IRQ_TYPE_LEVEL_HIGH>;
			clocks = <&clk_peri PERI2_UART4_SCLK_EN>, <&clk_peri PERI2_UART4_PCLK_EN>;
			clock-names = "baudclk", "apb_pclk";
			/* Firmware has already configured the boot console UART. */
			reg-shift = <2>;
			reg-io-width = <4>;
		};

		uart5: serial@8402000 {
			compatible = "snps,dw-apb-uart";
			reg = <0x00 0x08402000 0x0 0x1000>;
			interrupt-parent = <&intc>;
			interrupts = <326 IRQ_TYPE_LEVEL_HIGH>;
			clocks = <&clk_peri PERI2_UART5_SCLK_EN>, <&clk_peri PERI2_UART5_PCLK_EN>;
			clock-names = "baudclk", "apb_pclk";
			resets = <&rst_peri2 PERI2_UART5_PRST>;
			reg-shift = <2>;
			reg-io-width = <4>;
		};

		uart6: serial@8403000 {
			compatible = "snps,dw-apb-uart";
			reg = <0x00 0x08403000 0x0 0x1000>;
			interrupt-parent = <&intc>;
			interrupts = <327 IRQ_TYPE_LEVEL_HIGH>;
			clocks = <&clk_peri PERI2_UART6_SCLK_EN>, <&clk_peri PERI2_UART6_PCLK_EN>;
			clock-names = "baudclk", "apb_pclk";
			resets = <&rst_peri2 PERI2_UART6_PRST>;
			reg-shift = <2>;
			reg-io-width = <4>;
		};

		uart7: serial@8404000 {
			compatible = "snps,dw-apb-uart";
			reg = <0x00 0x08404000 0x0 0x1000>;
			interrupt-parent = <&intc>;
			interrupts = <328 IRQ_TYPE_LEVEL_HIGH>;
			clocks = <&clk_peri PERI2_UART7_SCLK_EN>, <&clk_peri PERI2_UART7_PCLK_EN>;
			clock-names = "baudclk", "apb_pclk";
			resets = <&rst_peri2 PERI2_UART7_PRST>;
			reg-shift = <2>;
			reg-io-width = <4>;
		};

		uart8: serial@8405000 {
			compatible = "snps,dw-apb-uart";
			reg = <0x00 0x08405000 0x0 0x1000>;
			interrupt-parent = <&intc>;
			interrupts = <329 IRQ_TYPE_LEVEL_HIGH>;
			clocks = <&clk_peri PERI2_UART8_SCLK_EN>, <&clk_peri PERI2_UART8_PCLK_EN>;
			clock-names = "baudclk", "apb_pclk";
			resets = <&rst_peri2 PERI2_UART8_PRST>;
			reg-shift = <2>;
			reg-io-width = <4>;
		};

		uart9: serial@8406000 {
			compatible = "snps,dw-apb-uart";
			reg = <0x00 0x08406000 0x0 0x1000>;
			interrupt-parent = <&intc>;
			interrupts = <330 IRQ_TYPE_LEVEL_HIGH>;
			clocks = <&clk_peri PERI2_UART9_SCLK_EN>, <&clk_peri PERI2_UART9_PCLK_EN>;
			clock-names = "baudclk", "apb_pclk";
			resets = <&rst_peri2 PERI2_UART9_PRST>;
			reg-shift = <2>;
			reg-io-width = <4>;
		};

		spi0: spi@2023000 {
			compatible = "snps,dw-apb-ssi";
			reg = <0x00 0x02023000 0x0 0x1000>;
			interrupt-parent = <&intc>;
			interrupts = <310 IRQ_TYPE_LEVEL_HIGH>;
			clocks = <&clk_peri PERI1_SPI0_SSI_CLK_EN>,
				 <&clk_peri PERI1_SPI0_PCLK_EN>;
			clock-names = "ssi_clk", "pclk";
			resets = <&rst_peri1 PERI1_SPI0_RST>;
			reset-names = "spi";
			power-domains = <&power_top>;
			dmas = <&dmac0 9>, <&dmac0 8>;
			dma-names = "tx", "rx";
			num-cs = <2>;
			#address-cells = <1>;
			#size-cells = <0>;
		};

		spi1: spi@8413000 {
			compatible = "snps,dw-apb-ssi";
			reg = <0x00 0x08413000 0x0 0x1000>;
			interrupt-parent = <&intc>;
			interrupts = <311 IRQ_TYPE_LEVEL_HIGH>;
			clocks = <&clk_peri PERI2_SPI1_SSI_CLK_EN>,
				 <&clk_peri PERI2_SPI1_PCLK_EN>;
			clock-names = "ssi_clk", "pclk";
			resets = <&rst_peri2 PERI2_SPI1_RST>;
			reset-names = "spi";
			power-domains = <&power_top>;
			dmas = <&dmac0 62>, <&dmac0 61>;
			dma-names = "tx", "rx";
			num-cs = <2>;
			#address-cells = <1>;
			#size-cells = <0>;
		};

		qspi0: spi@1000000 {
			compatible = "zhihe,a210-qspi", "snps,dwc-ssi-1.01a";
			reg = <0x00 0x01000000 0x0 0x4000>;
			interrupt-parent = <&intc>;
			interrupts = <308 IRQ_TYPE_LEVEL_HIGH>;
			clocks = <&clk_peri PERI1_QSPI0_SSI_CLK_EN>,
				 <&clk_peri PERI1_QSPI0_PCLK_EN>;
			clock-names = "ssi_clk", "pclk";
			resets = <&rst_peri1 PERI1_QSPI0_SSI_RST>,
				 <&rst_peri1 PERI1_QSPI0_PRST>;
			power-domains = <&power_top>;
			num-cs = <2>;
			#address-cells = <1>;
			#size-cells = <0>;
		};

		qspi1: spi@8428000 {
			compatible = "zhihe,a210-qspi", "snps,dwc-ssi-1.01a";
			reg = <0x00 0x08428000 0x0 0x4000>;
			interrupt-parent = <&intc>;
			interrupts = <309 IRQ_TYPE_LEVEL_HIGH>;
			clocks = <&clk_peri PERI2_QSPI1_SSI_CLK_EN>,
				 <&clk_peri PERI2_QSPI1_PCLK_EN>;
			clock-names = "ssi_clk", "pclk";
			resets = <&rst_peri2 PERI2_QSPI1_SSI_RST>,
				 <&rst_peri2 PERI2_QSPI1_PRST>;
			power-domains = <&power_top>;
			num-cs = <2>;
			#address-cells = <1>;
			#size-cells = <0>;
		};

		pwm0: pwm@202a000 {
			compatible = "zhihe,a210-pwm", "thead,th1520-pwm";
			reg = <0 0x0202a000 0 0x1000>;
			clocks = <&clk_peri PERI1_PWM0_CCLK_EN>;
			power-domains = <&power_pwm>;
			#pwm-cells = <3>;
			status = "disabled";
		};

		pwm1: pwm@841a000 {
			compatible = "zhihe,a210-pwm", "thead,th1520-pwm";
			reg = <0 0x0841a000 0 0x1000>;
			clocks = <&clk_peri PERI2_PWM1_CCLK_EN>;
			power-domains = <&power_pwm>;
			#pwm-cells = <3>;
			status = "disabled";
		};

		pwm2: pwm@841b000 {
			compatible = "zhihe,a210-pwm", "thead,th1520-pwm";
			reg = <0 0x0841b000 0 0x1000>;
			clocks = <&clk_peri PERI2_PWM2_CCLK_EN>;
			power-domains = <&power_pwm>;
			#pwm-cells = <3>;
			status = "disabled";
		};

		adc: adc@5a0000 {
			compatible = "zhihe,a210-adc";
			reg = <0 0x005a0000 0 0x1000>;
			clocks = <&clk_peri PERI3_ADC_PCLK_EN>;
			resets = <&rst_peri3 PERI3_ADC_PRST>;
			interrupt-parent = <&intc>;
			interrupts = <260 IRQ_TYPE_LEVEL_HIGH>;
			power-domains = <&power_top>;
			#io-channel-cells = <1>;
			status = "disabled";
		};

		emmc: mmc@500000 {
			compatible = "zhihe,a210-dwcmshc";
			reg = <0x0 0x00500000 0x0 0x10000>;
			interrupt-parent = <&intc>;
			interrupts = <265 IRQ_TYPE_LEVEL_HIGH>;
			clocks = <&clk_peri PERI3_EMMC_SDIO_REF_CLK_CG_EN>,
					 <&clk_peri PERI3_EMMC_HCLK_EN>;
			clock-names = "core", "bus";
			power-domains = <&power_emmc>;
		};

		sdio: mmc@510000 {
			compatible = "zhihe,a210-dwcmshc";
			reg = <0 0x00510000 0 0x10000>;
			interrupt-parent = <&intc>;
			interrupts = <337 IRQ_TYPE_LEVEL_HIGH>;
			clocks = <&clk_peri PERI3_EMMC_SDIO_REF_CLK_CG_EN>,
				 <&clk_peri PERI3_SDIO_HCLK_EN>;
			clock-names = "core", "bus";
			power-domains = <&power_sdio>;
			status = "disabled";
		};

		clk_aon: clock-controller@30844000 {
			compatible = "zhihe,a210-aon-clk";
			reg = <0 0x30844000 0 0x1c>;
			clocks = <&aon_110m>, <&osc_24m>, <&aon_rc>, <&osc_32k>;
			clock-names = "high", "osc", "rc", "rtc";
			#clock-cells = <1>;
		};


		clk_usb: clock-controller@8000000 {
			compatible = "zhihe,a210-usb-clk";
			reg = <0 0x08000000 0 0x24>;
			reg-names = "usb-clk-en";
			#clock-cells = <1>;
		};

		usb31_usb2_phy: phy@8001080 {
			compatible = "zhihe,a210-usb31-usb2-phy";
			reg = <0 0x08001080 0 0x28>;
			clocks = <&clk_usb USB31_PCLK_EN>;
			clock-names = "apb";
			resets = <&rst_usb USB_USB31_PHY_RST>;
			reset-names = "phy";
			power-domains = <&power_usb>;
			#phy-cells = <0>;
			status = "disabled";
		};

		usb3_phy: phy@807c000 {
			compatible = "zhihe,a210-c10-phy";
			reg = <0 0x0807c000 0 0x100>;
			clocks = <&clk_usb C10PHY_PCLK_EN>,
				 <&clk_usb USB31_REF_CLK_EN>,
				 <&clk_usb C10PHY_SUSPEND_CLK_EN>;
			clock-names = "apb", "ref", "suspend";
			resets = <&rst_usb USB_C10PHY_APBS_PRST>,
				 <&rst_usb USB_C10PHY_PHY_RST>;
			reset-names = "apb", "phy";
			power-domains = <&power_usb>;
			#phy-cells = <0>;
			status = "disabled";
		};

		usb3: usb@8100000 {
			compatible = "zhihe,a210-dwc3", "snps,dwc3";
			reg = <0 0x08100000 0 0x100000>;
			interrupt-parent = <&intc>;
			interrupts = <183 IRQ_TYPE_LEVEL_HIGH>;
			clocks = <&clk_usb USB31_BUS_CLK_EN>,
				 <&clk_usb USB31_REF_CLK_EN>,
				 <&clk_usb USB31_SUSPEND_CLK_EN>;
			clock-names = "bus_early", "ref", "suspend";
			resets = <&rst_usb USB_USB31_VCC_RST>;
			phys = <&usb31_usb2_phy>, <&usb3_phy>;
			phy-names = "usb2-phy", "usb3-phy";
			power-domains = <&power_usb>;
			status = "disabled";
		};

		usb2_phy0: phy@8300000 {
			compatible = "zhihe,a210-usb2-phy";
			reg = <0 0x08300000 0 0x20>;
			clocks = <&clk_usb USB20_SYSREG_PCLK>;
			clock-names = "apb";
			resets = <&rst_usb USB_USB20_BLK_USB0_PHY_PON_RESET>;
			reset-names = "phy";
			power-domains = <&power_usb>;
			#phy-cells = <0>;
			status = "disabled";
		};

		usb2_0: usb@8200000 {
			compatible = "zhihe,a210-usb", "snps,dwc2";
			reg = <0 0x08200000 0 0x40000>;
			interrupt-parent = <&intc>;
			interrupts = <181 IRQ_TYPE_LEVEL_HIGH>;
			clocks = <&clk_usb USB20_WRAP0_HCLK>;
			clock-names = "otg";
			resets = <&rst_usb USB_USB20_BLK_USB2_WRAP0_HRST>;
			reset-names = "dwc2";
			phys = <&usb2_phy0>;
			phy-names = "usb2-phy";
			power-domains = <&power_usb>;
			maximum-speed = "high-speed";
			g-rx-fifo-size = <275>;
			g-np-tx-fifo-size = <16>;
			g-tx-fifo-size = <256 128 128 64 64 32>;
			status = "disabled";
		};

		usb2_phy1: phy@8301000 {
			compatible = "zhihe,a210-usb2-phy1";
			reg = <0 0x08301000 0 0x20>;
			clocks = <&clk_usb USB20_SYSREG_PCLK>;
			clock-names = "apb";
			resets = <&rst_usb USB_USB20_BLK_USB1_PHY_PON_RESET>;
			reset-names = "phy";
			power-domains = <&power_usb>;
			#phy-cells = <0>;
			status = "disabled";
		};

		usb2_1: usb@8240000 {
			compatible = "zhihe,a210-usb", "snps,dwc2";
			reg = <0 0x08240000 0 0x40000>;
			interrupt-parent = <&intc>;
			interrupts = <182 IRQ_TYPE_LEVEL_HIGH>;
			clocks = <&clk_usb USB20_WRAP1_HCLK>;
			clock-names = "otg";
			resets = <&rst_usb USB_USB20_BLK_USB2_WRAP1_HRST>;
			reset-names = "dwc2";
			phys = <&usb2_phy1>;
			phy-names = "usb2-phy";
			power-domains = <&power_usb>;
			maximum-speed = "high-speed";
			g-rx-fifo-size = <275>;
			g-np-tx-fifo-size = <16>;
			g-tx-fifo-size = <256 128 128 64 64 32>;
			status = "disabled";
		};

		clk_pcie: clock-controller@a000000 {
			compatible = "zhihe,a210-pcie-clk";
			reg = <0 0x0a000000 0 0x28>;
			reg-names = "pcie-clk-en";
			#clock-cells = <1>;
		};

		e16phy: phy@a180000 {
			compatible = "zhihe,a210-e16-phy";
			reg = <0 0x0a180000 0 0x1000>,
			      <0 0x0a100000 0 0x40000>,
			      <0 0x0a140000 0 0x40000>;
			reg-names = "sysreg", "phy0", "phy1";
			resets = <&rst_pcie PCIE_E16PHY_APBS_PRST>,
				 <&rst_pcie PCIE_E16PHY_PHY_RST>;
			reset-names = "apb", "phy";
			#phy-cells = <0>;
			status = "disabled";
		};

		sata: sata@a200000 {
			compatible = "snps,dwc-ahci";
			reg = <0 0x0a200000 0 0x100000>;
			interrupt-parent = <&intc>;
			interrupts = <170 IRQ_TYPE_LEVEL_HIGH>;
			clocks = <&clk_pcie SATA_GEN3X2_ACLK_EN>,
				 <&clk_pcie SATA_PMALIVE_CLK_EN>;
			clock-names = "aclk", "pmalive";
			resets = <&rst_pcie PCIE_SATA_ARESET>,
				 <&rst_pcie PCIE_SATA_RST_PMALIVE>;
			reset-names = "arst", "pmalive";
			power-domains = <&power_sata>;
			#address-cells = <1>;
			#size-cells = <0>;
			status = "disabled";

			sata0: sata-port@0 {
				reg = <0>;
				phys = <&e16phy>;
				phy-names = "sata-phy";
			};

			sata1: sata-port@1 {
				reg = <1>;
				phys = <&e16phy>;
				phy-names = "sata-phy";
			};
		};

		pcie0: pcie@b000000 {
			compatible = "zhihe,a210-pcie";
			reg = <0 0x0b000000 0 0x800000>,
			      <0x18 0 0 0x200000>, <0 0x0a004000 0 0x1000>;
			reg-names = "dbi", "config", "app";
			device_type = "pci";
			#address-cells = <3>;
			#size-cells = <2>;
			#interrupt-cells = <1>;
			bus-range = <0 255>;
			ranges = <0x01000000 0 0 0x18 0x200000 0 0x10000>,
				 <0x02000000 0 0x40100000 0 0x40100000 0 0x800000>,
				 <0x43000000 0x18 0x300000 0x18 0x300000
				  0 0x800000>;
			interrupt-parent = <&intc>;
			interrupts = <139 IRQ_TYPE_LEVEL_HIGH>;
			interrupt-names = "msi";
			interrupt-map-mask = <0 0 0 7>;
			interrupt-map = <0 0 0 1 &intc 140 IRQ_TYPE_LEVEL_HIGH>,
					<0 0 0 2 &intc 141 IRQ_TYPE_LEVEL_HIGH>,
					<0 0 0 3 &intc 142 IRQ_TYPE_LEVEL_HIGH>,
					<0 0 0 4 &intc 143 IRQ_TYPE_LEVEL_HIGH>;
			clocks = <&clk_pcie PCIE_DM_GEN3X4_AUX_CLK_EN>,
				 <&clk_pcie PCIE_DM_GEN3X4_SLV_ACLK_EN>,
				 <&clk_pcie PCIE_DM_GEN3X4_MST_ACLK_EN>,
				 <&clk_pcie PCIE_DM_GEN3X4_PCLK_EN>;
			clock-names = "aux", "slv", "mstr", "dbi";
			resets = <&rst_pcie PCIE_DM_GEN3X4_APBS_PRST>,
				 <&rst_pcie PCIE_DM_GEN3X4_POWER_UP_RST>;
			reset-names = "dbi", "pwr";
			power-domains = <&power_pcie0>;
			phys = <&e16phy>;
			phy-names = "pcie";
			num-lanes = <4>;
			max-link-speed = <3>;
			status = "disabled";
		};

		pcie1: pcie@b800000 {
			compatible = "zhihe,a210-pcie";
			reg = <0 0x0b800000 0 0x800000>,
			      <0x1e 0 0 0x20000>, <0 0x0a005000 0 0x1000>;
			reg-names = "dbi", "config", "app";
			device_type = "pci";
			#address-cells = <3>;
			#size-cells = <2>;
			#interrupt-cells = <1>;
			bus-range = <0 255>;
			ranges = <0x01000000 0 0 0x1e 0x200000 0 0x10000>,
				 <0x02000000 0 0x50100000 0 0x50100000 0 0x800000>,
				 <0x43000000 0x1e 0x300000 0x1e 0x300000
				  0 0x800000>;
			interrupt-parent = <&intc>;
			interrupts = <158 IRQ_TYPE_LEVEL_HIGH>;
			interrupt-names = "msi";
			interrupt-map-mask = <0 0 0 7>;
			interrupt-map = <0 0 0 1 &intc 159 IRQ_TYPE_LEVEL_HIGH>,
					<0 0 0 2 &intc 160 IRQ_TYPE_LEVEL_HIGH>,
					<0 0 0 3 &intc 161 IRQ_TYPE_LEVEL_HIGH>,
					<0 0 0 4 &intc 162 IRQ_TYPE_LEVEL_HIGH>;
			clocks = <&clk_pcie PCIE_RP_GEN3X1_AUX_CLK_EN>,
				 <&clk_pcie PCIE_RP_GEN3X1_SLV_ACLK_EN>,
				 <&clk_pcie PCIE_RP_GEN3X1_MST_ACLK_EN>,
				 <&clk_pcie PCIE_RP_GEN3X1_PCLK_EN>;
			clock-names = "aux", "slv", "mstr", "dbi";
			resets = <&rst_pcie PCIE_RP_GEN3X1_APBS_PRST>,
				 <&rst_pcie PCIE_RP_GEN3X1_POWER_UP_RST>;
			reset-names = "dbi", "pwr";
			power-domains = <&power_pcie1>;
			phys = <&e16phy>;
			phy-names = "pcie";
			num-lanes = <1>;
			max-link-speed = <3>;
			status = "disabled";
		};

		clk_gpu: clock-controller@6d02200 {
			compatible = "zhihe,a210-gpu-clk";
			reg = <0 0x06d02200 0 0x200>,
			      <0 0x06e06200 0 0x200>;
			reg-names = "gpu-ss-pwrap-clk-en", "gpu-ss-top-clk-en";
			power-domains = <&power_gpu>;
			#clock-cells = <1>;
		};

		gpu: gpu@6c00000 {
			compatible = "zhihe,a210-gpu", "img,img-bxm-4-64",
				     "img,img-rogue";
			reg = <0 0x06c00000 0 0x100000>;
			interrupt-parent = <&intc>;
			interrupts = <72 IRQ_TYPE_LEVEL_HIGH>;
			clocks = <&clk_gpu SW_PWR_WRAP_GPU_CORE_CLK_EN>,
				 <&clk_gpu SW_PWR_WRAP_DFMU_CORE_CLK_EN>,
				 <&clk_gpu SW_PWR_WRAP_GPU_SYS_CLK_EN>;
			clock-names = "core", "mem", "sys";
			resets = <&rst_gpu GPU_PWR_WRAP_RGX_HOOD_RST>;
			power-domains = <&power_gpu>;
			status = "disabled";
		};

		clk_vo: clock-controller@6720200 {
			compatible = "zhihe,a210-vo-clk";
			reg = <0 0x06720200 0 0xc>, <0 0x06720048 0 4>;
			reg-names = "vo-clk", "vo-path-ctrl";
			#clock-cells = <1>;
		};

		dc8200: display@6400000 {
			compatible = "zhihe,a210-dc8200", "verisilicon,dc";
			reg = <0 0x06400000 0 0x10000>;
			interrupt-parent = <&intc>;
			interrupts = <218 IRQ_TYPE_LEVEL_HIGH>;
			clocks = <&clk_vo VO_DPUC_CLK_EN>,
				 <&clk_vo VO_DPU_ACLK_EN>,
				 <&clk_vo VO_DPU_HCLK_EN>,
				 <&clk_vo VO_CH0_PIXCLK_EN>,
				 <&clk_vo VO_CH1_PIXCLK_EN>;
			clock-names = "core", "axi", "ahb", "pix0", "pix1";
			resets = <&rst_vo VO_DPU_CRST>, <&rst_vo VO_DPU_ARST>,
				 <&rst_vo VO_DPU_HRST>;
			reset-names = "core", "axi", "ahb";
			power-domains = <&power_vo>;
			status = "disabled";

			ports {
				#address-cells = <1>;
				#size-cells = <0>;
				port@1 {
					reg = <1>;
					#address-cells = <1>;
					#size-cells = <0>;
					dc8200_hdmi_out: endpoint@1 {
						reg = <1>;
						remote-endpoint = <&hdmi_in>;
					};
				};
			};
		};

		hdmi: hdmi@6600000 {
			compatible = "zhihe,a210-dw-hdmi";
			reg = <0 0x06600000 0 0x40000>;
			reg-io-width = <4>;
			interrupt-parent = <&intc>;
			interrupts = <216 IRQ_TYPE_LEVEL_HIGH>;
			clocks = <&clk_vo VO_HDMI_PCLK_EN>,
				 <&clk_vo VO_HDMI_SFRCLK_EN>,
				 <&clk_vo VO_CEC_CLK_EN>,
				 <&clk_vo VO_HDMI_PIXCLK>;
			clock-names = "iahb", "isfr", "cec", "pix";
			resets = <&rst_vo VO_HDMI_MAIN_RST>,
				 <&rst_vo VO_HDMI_PRST>;
			reset-names = "main", "apb";
			power-domains = <&power_vo>;
			assigned-clocks = <&clk_vo VO_HDMI_PIXCLK>;
			assigned-clock-parents = <&clk_vo VO_CH1_PIXCLK_EN>;
			status = "disabled";

			ports {
				#address-cells = <1>;
				#size-cells = <0>;
				port@0 {
					reg = <0>;
					hdmi_in: endpoint {
						remote-endpoint = <&dc8200_hdmi_out>;
					};
				};
				port@1 {
					reg = <1>;
					hdmi_out: endpoint { };
				};
			};
		};

		gmac0_sys: syscon@210f000 {
			compatible = "zhihe,a210-gmac-syscon", "syscon";
			reg = <0x00 0x0210f000 0x0 0x20>;
		};

		gmac1_sys: syscon@211f000 {
			compatible = "zhihe,a210-gmac-syscon", "syscon";
			reg = <0x00 0x0211f000 0x0 0x20>;
		};

		gmac0: ethernet@2100000 {
			compatible = "zhihe,a210-dwmac", "snps,dwmac-5.40a";
			reg = <0x00 0x02100000 0x0 0x10000>;
			reg-names = "gmac";
			interrupt-parent = <&intc>;
			interrupts = <277 IRQ_TYPE_LEVEL_HIGH>;
			interrupt-names = "macirq";
			clocks = <&clk_peri PERI1_GMAC0_ACLK_EN>,
				 <&clk_peri PERI1_GMAC0_HCLK_EN>,
				 <&clk_peri PERI1_X2H_GMAC0_ACLK_EN>,
				 <&clk_peri PERI1_X2H_GMAC0_HCLK_EN>;
			clock-names = "stmmaceth", "pclk", "x2h_aclk", "x2h_hclk";
			resets = <&rst_peri1 PERI1_GMAC0_RST>,
				 <&rst_peri1 PERI1_GMAC0_X2H_RST>;
			reset-names = "stmmaceth", "ahb";
			power-domains = <&power_top>;
			snps,pbl = <32>;
			snps,fixed-burst;
			snps,axi-config = <&stmmac_axi_setup>;
			snps,tso;
			zhihe,gmacsys = <&gmac0_sys>;
			status = "disabled";

			mdio0: mdio {
				compatible = "snps,dwmac-mdio";
				#address-cells = <1>;
				#size-cells = <0>;
			};
		};

		gmac1: ethernet@2110000 {
			compatible = "zhihe,a210-dwmac", "snps,dwmac-5.40a";
			reg = <0x00 0x02110000 0x0 0x10000>;
			reg-names = "gmac";
			interrupt-parent = <&intc>;
			interrupts = <288 IRQ_TYPE_LEVEL_HIGH>;
			interrupt-names = "macirq";
			clocks = <&clk_peri PERI1_GMAC1_ACLK_EN>,
				 <&clk_peri PERI1_GMAC1_HCLK_EN>,
				 <&clk_peri PERI1_X2H_GMAC1_ACLK_EN>,
				 <&clk_peri PERI1_X2H_GMAC1_HCLK_EN>;
			clock-names = "stmmaceth", "pclk", "x2h_aclk", "x2h_hclk";
			resets = <&rst_peri1 PERI1_GMAC1_RST>,
				 <&rst_peri1 PERI1_GMAC1_X2H_RST>;
			reset-names = "stmmaceth", "ahb";
			power-domains = <&power_top>;
			snps,pbl = <32>;
			snps,fixed-burst;
			snps,axi-config = <&stmmac_axi_setup>;
			snps,tso;
			zhihe,gmacsys = <&gmac1_sys>;
			status = "disabled";

			mdio1: mdio {
				compatible = "snps,dwmac-mdio";
				#address-cells = <1>;
				#size-cells = <0>;
			};
		};

		aon_padctrl: aon-padctrl@30848000 {
			compatible = "zhihe,a210-aon-pinctrl";
			reg = <0x00 0x30848000 0x0 0x2000>;
			clocks = <&aon_110m>;
			clock-names = "pclk";
		};

		peri1_padctrl: peri1-padctrl@2026000 {
			compatible = "zhihe,a210-peri1-pinctrl";
			reg = <0x00 0x02026000 0x0 0x1000>;
			clocks = <&clk_peri PERI1_PAD_CTRL_PCLK_EN>;
			clock-names = "pclk";
		};

		peri2_padctrl: peri2-padctrl@8411000 {
			compatible = "zhihe,a210-peri2-pinctrl";
			reg = <0x00 0x08411000 0x0 0x1000>;
			clocks = <&clk_peri PERI2_PAD_CTRL_PCLK_EN>;
			clock-names = "pclk";
		};

		peri3_padctrl: peri3-padctrl@542000 {
			compatible = "zhihe,a210-peri3-pinctrl";
			reg = <0x00 0x00542000 0x0 0x1000>;
			clocks = <&clk_peri PERI3_PAD_CTRL_PCLK_EN>;
			clock-names = "pclk";
		};

		aon_gpio0: gpio@30841000 {
			compatible = "snps,dw-apb-gpio";
			reg = <0x00 0x30841000 0x0 0x1000>;
			#address-cells = <1>;
			#size-cells = <0>;
			clocks = <&aon_110m>, <&osc_32k>;
			clock-names = "bus", "db";

			ao_gpio0: gpio-controller@0 {
				compatible = "snps,dw-apb-gpio-port";
				gpio-controller;
				#gpio-cells = <2>;
				ngpios = <32>;
				gpio-ranges = <&aon_padctrl 0 7 15>,
				      <&aon_padctrl 21 22 11>;
				reg = <0>;

				interrupt-controller;
				#interrupt-cells = <2>;
				interrupt-parent = <&intc>;
				interrupts = <17 IRQ_TYPE_LEVEL_HIGH>;
			};
		};

		aon_gpio1: gpio@30897000 {
			compatible = "snps,dw-apb-gpio";
			reg = <0x00 0x30897000 0x0 0x1000>;
			#address-cells = <1>;
			#size-cells = <0>;
			clocks = <&aon_110m>, <&osc_32k>;
			clock-names = "bus", "db";

			ao_gpio1: gpio-controller@0 {
				compatible = "snps,dw-apb-gpio-port";
				gpio-controller;
				#gpio-cells = <2>;
				ngpios = <10>;
				gpio-ranges = <&aon_padctrl 0 33 10>;
				reg = <0>;

				interrupt-controller;
				#interrupt-cells = <2>;
				interrupt-parent = <&intc>;
				interrupts = <10 IRQ_TYPE_LEVEL_HIGH>;
			};
		};

		peri1_gpio0: gpio@2012000 {
			compatible = "zhihe,a210-gpio", "snps,dw-apb-gpio";
			reg = <0x00 0x02012000 0x0 0x1000>;
			#address-cells = <1>;
			#size-cells = <0>;
			clocks = <&clk_peri PERI1_GPIO0_PCLK_EN>,
				 <&clk_peri PERI1_GPIO0_DBCLK_EN>;
			clock-names = "bus", "db";
			power-domains = <&power_top>;

			gpio0: gpio-controller@0 {
				compatible = "snps,dw-apb-gpio-port";
				gpio-controller;
				#gpio-cells = <2>;
				ngpios = <32>;
				gpio-ranges = <&peri1_padctrl 0 0 32>;
				reg = <0>;

				interrupt-controller;
				#interrupt-cells = <2>;
				interrupt-parent = <&intc>;
				interrupts = <289 IRQ_TYPE_LEVEL_HIGH>;
			};
		};

		peri1_gpio1: gpio@2013000 {
			compatible = "zhihe,a210-gpio", "snps,dw-apb-gpio";
			reg = <0x00 0x02013000 0x0 0x1000>;
			#address-cells = <1>;
			#size-cells = <0>;
			clocks = <&clk_peri PERI1_GPIO1_PCLK_EN>,
				 <&clk_peri PERI1_GPIO1_DBCLK_EN>;
			clock-names = "bus", "db";
			power-domains = <&power_top>;

			gpio1: gpio-controller@0 {
				compatible = "snps,dw-apb-gpio-port";
				gpio-controller;
				#gpio-cells = <2>;
				ngpios = <18>;
				gpio-ranges = <&peri1_padctrl 0 32 18>;
				reg = <0>;

				interrupt-controller;
				#interrupt-cells = <2>;
				interrupt-parent = <&intc>;
				interrupts = <290 IRQ_TYPE_LEVEL_HIGH>;
			};
		};

		peri2_gpio2: gpio@8410000 {
			compatible = "zhihe,a210-gpio", "snps,dw-apb-gpio";
			reg = <0x00 0x08410000 0x0 0x1000>;
			#address-cells = <1>;
			#size-cells = <0>;
			clocks = <&clk_peri PERI2_GPIO2_PCLK_EN>,
				 <&clk_peri PERI2_GPIO2_DBCLK_EN>;
			clock-names = "bus", "db";
			power-domains = <&power_top>;

			gpio2: gpio-controller@0 {
				compatible = "snps,dw-apb-gpio-port";
				gpio-controller;
				#gpio-cells = <2>;
				ngpios = <32>;
				gpio-ranges = <&peri2_padctrl 0 0 32>;
				reg = <0>;

				interrupt-controller;
				#interrupt-cells = <2>;
				interrupt-parent = <&intc>;
				interrupts = <291 IRQ_TYPE_LEVEL_HIGH>;
			};
		};

		peri2_gpio3: gpio@8412000 {
			compatible = "zhihe,a210-gpio", "snps,dw-apb-gpio";
			reg = <0x00 0x08412000 0x0 0x1000>;
			#address-cells = <1>;
			#size-cells = <0>;
			clocks = <&clk_peri PERI2_GPIO3_PCLK_EN>,
				 <&clk_peri PERI2_GPIO3_DBCLK_EN>;
			clock-names = "bus", "db";
			power-domains = <&power_top>;

			gpio3: gpio-controller@0 {
				compatible = "snps,dw-apb-gpio-port";
				gpio-controller;
				#gpio-cells = <2>;
				ngpios = <11>;
				gpio-ranges = <&peri2_padctrl 0 32 11>;
				reg = <0>;

				interrupt-controller;
				#interrupt-cells = <2>;
				interrupt-parent = <&intc>;
				interrupts = <292 IRQ_TYPE_LEVEL_HIGH>;
			};
		};

		peri3_gpio: gpio@550000 {
			compatible = "zhihe,a210-gpio", "snps,dw-apb-gpio";
			reg = <0x00 0x00550000 0x0 0x10000>;
			#address-cells = <1>;
			#size-cells = <0>;
			clocks = <&clk_peri PERI3_GPIO4_PCLK_EN>,
				 <&clk_peri PERI3_GPIO4_DBCLK_EN>;
			clock-names = "bus", "db";
			power-domains = <&power_top>;

			gpio4: gpio-controller@0 {
				compatible = "snps,dw-apb-gpio-port";
				gpio-controller;
				#gpio-cells = <2>;
				ngpios = <6>;
				gpio-ranges = <&peri3_padctrl 0 0 6>;
				reg = <0>;

				interrupt-controller;
				#interrupt-cells = <2>;
				interrupt-parent = <&intc>;
				interrupts = <52 IRQ_TYPE_LEVEL_HIGH>;
			};
		};

		i2c0: i2c@2020000 {
			compatible = "zhihe,a210-i2c", "snps,designware-i2c";
			reg = <0x00 0x02020000 0x0 0x1000>;
			interrupt-parent = <&intc>;
			interrupts = <293 IRQ_TYPE_LEVEL_HIGH>;
			clocks = <&clk_peri PERI1_I2C0_IC_CLK_EN>,
				 <&clk_peri PERI1_I2C0_PCLK_EN>;
			clock-names = "ref", "pclk";
			resets = <&rst_peri1 PERI1_I2C0_RST>;
			power-domains = <&power_top>;
			dmas = <&dmac0 21>, <&dmac0 20>;
			dma-names = "tx", "rx";
			#address-cells = <1>;
			#size-cells = <0>;
		};

		i2c1: i2c@2021000 {
			compatible = "zhihe,a210-i2c", "snps,designware-i2c";
			reg = <0x00 0x02021000 0x0 0x1000>;
			interrupt-parent = <&intc>;
			interrupts = <294 IRQ_TYPE_LEVEL_HIGH>;
			clocks = <&clk_peri PERI1_I2C1_IC_CLK_EN>,
				 <&clk_peri PERI1_I2C1_PCLK_EN>;
			clock-names = "ref", "pclk";
			resets = <&rst_peri1 PERI1_I2C1_RST>;
			power-domains = <&power_top>;
			#address-cells = <1>;
			#size-cells = <0>;
		};

		i2c2: i2c@2022000 {
			compatible = "zhihe,a210-i2c", "snps,designware-i2c";
			reg = <0x00 0x02022000 0x0 0x1000>;
			interrupt-parent = <&intc>;
			interrupts = <295 IRQ_TYPE_LEVEL_HIGH>;
			clocks = <&clk_peri PERI1_I2C2_IC_CLK_EN>,
				 <&clk_peri PERI1_I2C2_PCLK_EN>;
			clock-names = "ref", "pclk";
			resets = <&rst_peri1 PERI1_I2C2_RST>;
			power-domains = <&power_top>;
			#address-cells = <1>;
			#size-cells = <0>;
		};

		i2c3: i2c@8415000 {
			compatible = "zhihe,a210-i2c", "snps,designware-i2c";
			reg = <0x00 0x08415000 0x0 0x1000>;
			interrupt-parent = <&intc>;
			interrupts = <296 IRQ_TYPE_LEVEL_HIGH>;
			clocks = <&clk_peri PERI2_I2C3_IC_CLK_EN>,
				 <&clk_peri PERI2_I2C3_PCLK_EN>;
			clock-names = "ref", "pclk";
			resets = <&rst_peri2 PERI2_I2C3_RST>;
			power-domains = <&power_top>;
			#address-cells = <1>;
			#size-cells = <0>;
		};

		i2c4: i2c@8416000 {
			compatible = "zhihe,a210-i2c", "snps,designware-i2c";
			reg = <0x00 0x08416000 0x0 0x1000>;
			interrupt-parent = <&intc>;
			interrupts = <297 IRQ_TYPE_LEVEL_HIGH>;
			clocks = <&clk_peri PERI2_I2C4_IC_CLK_EN>,
				 <&clk_peri PERI2_I2C4_PCLK_EN>;
			clock-names = "ref", "pclk";
			resets = <&rst_peri2 PERI2_I2C4_RST>;
			power-domains = <&power_top>;
			#address-cells = <1>;
			#size-cells = <0>;
		};

		i2c5: i2c@8417000 {
			compatible = "zhihe,a210-i2c", "snps,designware-i2c";
			reg = <0x00 0x08417000 0x0 0x1000>;
			interrupt-parent = <&intc>;
			interrupts = <298 IRQ_TYPE_LEVEL_HIGH>;
			clocks = <&clk_peri PERI2_I2C5_IC_CLK_EN>,
				 <&clk_peri PERI2_I2C5_PCLK_EN>;
			clock-names = "ref", "pclk";
			resets = <&rst_peri2 PERI2_I2C5_RST>;
			power-domains = <&power_top>;
			#address-cells = <1>;
			#size-cells = <0>;
		};

		i2c6: i2c@8418000 {
			compatible = "zhihe,a210-i2c", "snps,designware-i2c";
			reg = <0x00 0x08418000 0x0 0x1000>;
			interrupt-parent = <&intc>;
			interrupts = <299 IRQ_TYPE_LEVEL_HIGH>;
			clocks = <&clk_peri PERI2_I2C6_IC_CLK_EN>,
				 <&clk_peri PERI2_I2C6_PCLK_EN>;
			clock-names = "ref", "pclk";
			resets = <&rst_peri2 PERI2_I2C6_RST>;
			power-domains = <&power_top>;
			#address-cells = <1>;
			#size-cells = <0>;
		};

		i2c7: i2c@8419000 {
			compatible = "zhihe,a210-i2c", "snps,designware-i2c";
			reg = <0x00 0x08419000 0x0 0x1000>;
			interrupt-parent = <&intc>;
			interrupts = <300 IRQ_TYPE_LEVEL_HIGH>;
			clocks = <&clk_peri PERI2_I2C7_IC_CLK_EN>,
				 <&clk_peri PERI2_I2C7_PCLK_EN>;
			clock-names = "ref", "pclk";
			resets = <&rst_peri2 PERI2_I2C7_RST>;
			power-domains = <&power_top>;
			#address-cells = <1>;
			#size-cells = <0>;
		};

		aoi2c1: i2c@30891000 {
			compatible = "snps,designware-i2c";
			reg = <0x00 0x30891000 0x0 0x1000>;
			interrupt-parent = <&intc>;
			interrupts = <20 IRQ_TYPE_LEVEL_HIGH>;
			clocks = <&clk_aon A210_AON_I2C1_IC_CLK>,
				 <&clk_aon A210_AON_I2C1_PCLK>;
			clock-names = "ref", "pclk";
			#address-cells = <1>;
			#size-cells = <0>;
			status = "disabled";
		};

		mbox_920: mailbox@321000 {
			compatible = "zhihe,a210-mailbox-v2";
			reg = <0x00 0x00321000 0x0 0x1000>,
			      <0x00 0x00320000 0x0 0x1000>,
			      <0x00 0x00311000 0x0 0x1000>;
			reg-names = "interrupt",
				    "local0",
				    "remote0";
			clocks = <&clk_peri PERI0_MBOX0_PCLK_EN>,
				 <&clk_peri PERI0_MBOX1_PCLK_EN>;
			resets = <&rst_peri0 PERI0_MBOX0_PRST>,
				 <&rst_peri0 PERI0_MBOX1_PRST>;
			interrupt-parent = <&intc>;
			interrupts = <336 IRQ_TYPE_LEVEL_HIGH>;
			zhihe,icu-cpu-id = <0>;
			#mbox-cells = <2>;
		};

		aon: aon-subsys@308f8000 {
			compatible = "zhihe,a210-aon";
			reg = <0x00 0x308f8000 0x0 0x10000>,
			      <0x00 0x30842018 0x0 0x4>,
			      <0x00 0x30846144 0x0 0x4>;
			reg-names = "aon-base",
				"aon-reset",
				"aon-sync";
			mboxes = <&mbox_920 1 0>;
			mbox-names = "aon0";
		};
	};
};
